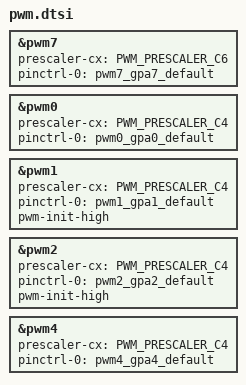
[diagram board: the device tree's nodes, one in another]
/* Copyright 2025 The ChromiumOS Authors
 * Use of this source code is governed by a BSD-style license that can be
 * found in the LICENSE file.
 */

/* Fan - use a prescaler for operation about 324 Hz */
/* Fan */
&pwm7 {
	status = "okay";
	prescaler-cx = <PWM_PRESCALER_C6>;
	pinctrl-0 = <&pwm7_gpa7_default>;
	pinctrl-names = "default";
};

/* Keyboard backlight*/
&pwm0 {
	status = "okay";
	prescaler-cx = <PWM_PRESCALER_C4>;
	pinctrl-0 = <&pwm0_gpa0_default>;
	pinctrl-names = "default";
};

/* Board LEDs - share one prescaler reference, all clocks must be configured
 * for 324 Hz or lower so LEDs work in low power mode.
 */

&pwm1 {
	status = "okay";
	prescaler-cx = <PWM_PRESCALER_C4>;
	pinctrl-0 = <&pwm1_gpa1_default>;
	pinctrl-names = "default";
	pwm-init-high;
};

&pwm2 {
	status = "okay";
	prescaler-cx = <PWM_PRESCALER_C4>;
	pinctrl-0 = <&pwm2_gpa2_default>;
	pinctrl-names = "default";
	pwm-init-high;
};

&pwm4 {
	status = "okay";
	prescaler-cx = <PWM_PRESCALER_C4>;
	pinctrl-0 = <&pwm4_gpa4_default>;
	pinctrl-names = "default";
};
